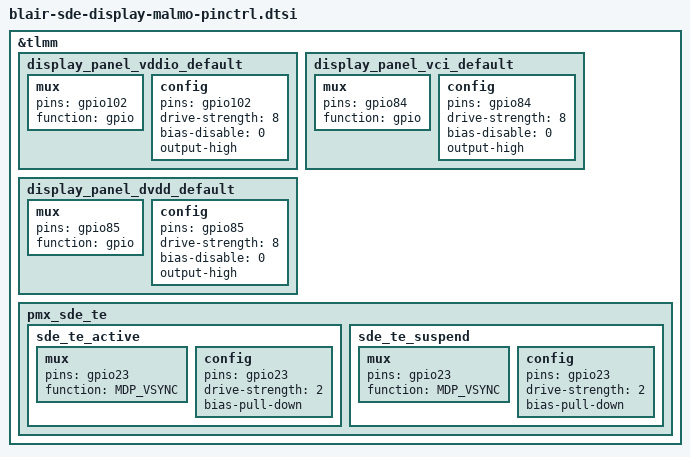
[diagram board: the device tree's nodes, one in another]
&tlmm {
	display_panel_vddio_default: display_panel_vddio_default {
		mux {
			pins = "gpio102";
			function = "gpio";
		};

		config {
			pins = "gpio102";
			drive-strength = <8>;
			bias-disable = <0>;
			output-high;
		};
	};

	display_panel_vci_default: display_panel_vci_default {
		mux {
			pins = "gpio84";
			function = "gpio";
		};

		config {
			pins = "gpio84";
			drive-strength = <8>;
			bias-disable = <0>;
			output-high;
		};
	};

	display_panel_dvdd_default: display_panel_dvdd_default {
		mux {
			pins = "gpio85";
			function = "gpio";
		};

		config {
			pins = "gpio85";
			drive-strength = <8>;
			bias-disable = <0>;
			output-high;
		};
	};

	pmx_sde_te: pmx_sde_te {
		sde_te_active: sde_te_active {
			mux {
				pins = "gpio23";
				function = "MDP_VSYNC";
			};

			config {
				pins = "gpio23";
				drive-strength = <2>;   /* 2 mA */
				bias-pull-down;         /* PULL DOWN */
			};
		};

		sde_te_suspend: sde_te_suspend {
			mux {
				pins = "gpio23";
				function = "MDP_VSYNC";
			};

			config {
				pins = "gpio23";
				drive-strength = <2>;   /* 2 mA */
				bias-pull-down;         /* PULL DOWN */
			};
		};
	};
};
